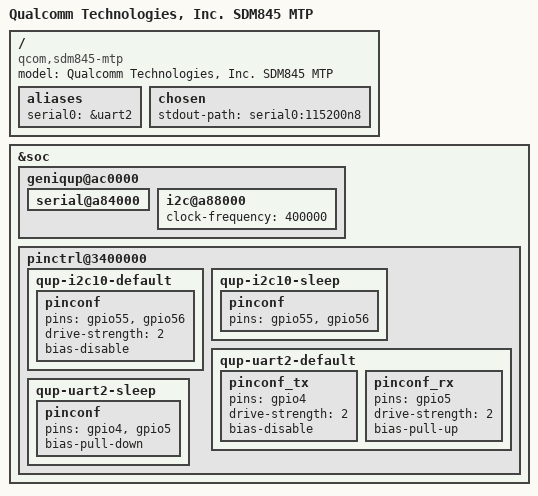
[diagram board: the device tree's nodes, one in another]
// SPDX-License-Identifier: GPL-2.0
/*
 * SDM845 MTP board device tree source
 *
 * Copyright (c) 2018, The Linux Foundation. All rights reserved.
 */

/dts-v1/;

#include "sdm845.dtsi"

/ {
	model = "Qualcomm Technologies, Inc. SDM845 MTP";
	compatible = "qcom,sdm845-mtp";

	aliases {
		serial0 = &uart2;
	};

	chosen {
		stdout-path = "serial0:115200n8";
	};
};

&soc {
	geniqup@ac0000 {
		status = "okay";

		serial@a84000 {
			status = "okay";
		};

		i2c@a88000 {
			clock-frequency = <400000>;
			status = "okay";
		};
	};

	pinctrl@3400000 {
		qup-i2c10-default {
			pinconf {
				pins = "gpio55", "gpio56";
				drive-strength = <2>;
				bias-disable;
			};
		};

		qup-i2c10-sleep {
			pinconf {
				pins = "gpio55", "gpio56";
			};
		};

		qup-uart2-default {
			pinconf_tx {
				pins = "gpio4";
				drive-strength = <2>;
				bias-disable;
			};

			pinconf_rx {
				pins = "gpio5";
				drive-strength = <2>;
				bias-pull-up;
			};
		};

		qup-uart2-sleep {
			pinconf {
				pins = "gpio4", "gpio5";
				bias-pull-down;
			};
		};
	};
};
